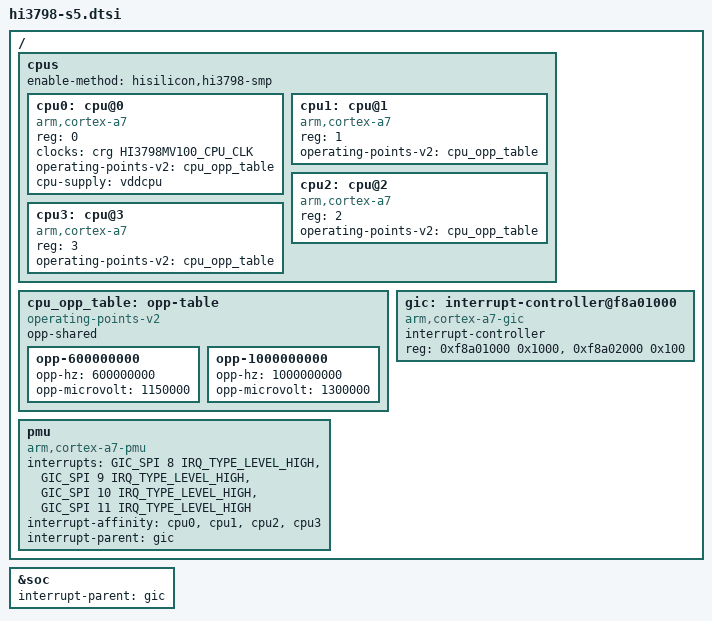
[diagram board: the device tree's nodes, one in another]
// SPDX-License-Identifier: GPL-2.0-or-later OR MIT
/*
 * Copyright (c) 2023 David Yang
 */

#include <dt-bindings/interrupt-controller/arm-gic.h>
#include "hi3798.dtsi"

/*
 * The CPU side of the 32-bit members of the family: four Cortex-A7 behind one
 * GIC-400, which is what the SDK's mach-hi3798mx platform covers. The PMU lines
 * are that controller's private peripheral interrupts, one per core, and they
 * are numbered 8 to 11 in the Hi3798MV100 interrupt map.
 */
/ {
	cpus {
		#address-cells = <1>;
		#size-cells = <0>;
		enable-method = "hisilicon,hi3798-smp";

		cpu0: cpu@0 {
			compatible = "arm,cortex-a7";
			device_type = "cpu";
			reg = <0>;
			clocks = <&crg HI3798MV100_CPU_CLK>;
			operating-points-v2 = <&cpu_opp_table>;
			cpu-supply = <&vddcpu>;
			#cooling-cells = <2>;
		};

		cpu1: cpu@1 {
			compatible = "arm,cortex-a7";
			device_type = "cpu";
			reg = <1>;
			operating-points-v2 = <&cpu_opp_table>;
			#cooling-cells = <2>;
		};

		cpu2: cpu@2 {
			compatible = "arm,cortex-a7";
			device_type = "cpu";
			reg = <2>;
			operating-points-v2 = <&cpu_opp_table>;
			#cooling-cells = <2>;
		};

		cpu3: cpu@3 {
			compatible = "arm,cortex-a7";
			device_type = "cpu";
			reg = <3>;
			operating-points-v2 = <&cpu_opp_table>;
			#cooling-cells = <2>;
		};
	};

	/*
	 * The cluster shares one clock and one rail, so all CPUs use a single
	 * shared table.  The voltages are the vendor's per-OPP upper bounds
	 * (msp/drv/include/hi_drv_pmoc.h: HI_VDD_MPU_OPP2_UV and HI_VDD_MPU_OPP4_UV)
	 * rather than the AVS minimum, which is the conservative choice here
	 * since this port does not implement the HPM/AVS hardware.
	 *
	 * The vendor's 1200 and 1500MHz points need 1420 and 1495mV and are left
	 * out for now: this board has no heatsink and has no use for them.
	 */
	cpu_opp_table: opp-table {
		compatible = "operating-points-v2";
		opp-shared;

		opp-600000000 {
			opp-hz = /bits/ 64 <600000000>;
			opp-microvolt = <1150000>;
		};

		opp-1000000000 {
			opp-hz = /bits/ 64 <1000000000>;
			opp-microvolt = <1300000>;
		};
	};

	gic: interrupt-controller@f8a01000 {
		compatible = "arm,cortex-a7-gic";
		#interrupt-cells = <3>;
		#address-cells = <0>;
		interrupt-controller;
		/* gic dist base, gic cpu base */
		reg = <0xf8a01000 0x1000>, <0xf8a02000 0x100>;
	};

	pmu: pmu {
		compatible = "arm,cortex-a7-pmu";
		interrupts = <GIC_SPI 8 IRQ_TYPE_LEVEL_HIGH>,
			<GIC_SPI 9 IRQ_TYPE_LEVEL_HIGH>,
			<GIC_SPI 10 IRQ_TYPE_LEVEL_HIGH>,
			<GIC_SPI 11 IRQ_TYPE_LEVEL_HIGH>;
		interrupt-affinity = <&cpu0>, <&cpu1>, <&cpu2>, <&cpu3>;
		interrupt-parent = <&gic>;
	};
};

/* Devices below the bus containers inherit their interrupt parent here. */
&soc {
	interrupt-parent = <&gic>;
};
